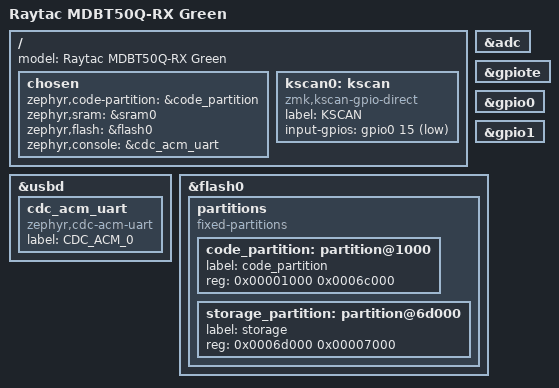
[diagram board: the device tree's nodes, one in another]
/dts-v1/;
#include <nordic/nrf52833_qiaa.dtsi>

/ {
	model = "Raytac MDBT50Q-RX Green";

	chosen {
		zephyr,code-partition = &code_partition;
		zephyr,sram = &sram0;
		zephyr,flash = &flash0;
		zephyr,console = &cdc_acm_uart;
	};

	kscan0: kscan {
		compatible = "zmk,kscan-gpio-direct";
		label = "KSCAN";
		input-gpios = <&gpio0 15 (GPIO_ACTIVE_LOW | GPIO_PULL_UP)>;
	};
};

&adc {
	status = "okay";
};

&gpiote {
	status = "okay";
};

&gpio0 {
	status = "okay";
};

&gpio1 {
	status = "okay";
};

&usbd {
	status = "okay";
	cdc_acm_uart: cdc_acm_uart {
		compatible = "zephyr,cdc-acm-uart";
		label = "CDC_ACM_0";
	};
};

&flash0 {
	partitions {
		compatible = "fixed-partitions";
		#address-cells = <1>;
		#size-cells = <1>;

		code_partition: partition@1000 {
			label = "code_partition";
			reg = <0x00001000 0x0006c000>;
		};

		storage_partition: partition@6d000 {
			label = "storage";
			reg = <0x0006d000 0x00007000>;
		};
	};
};
